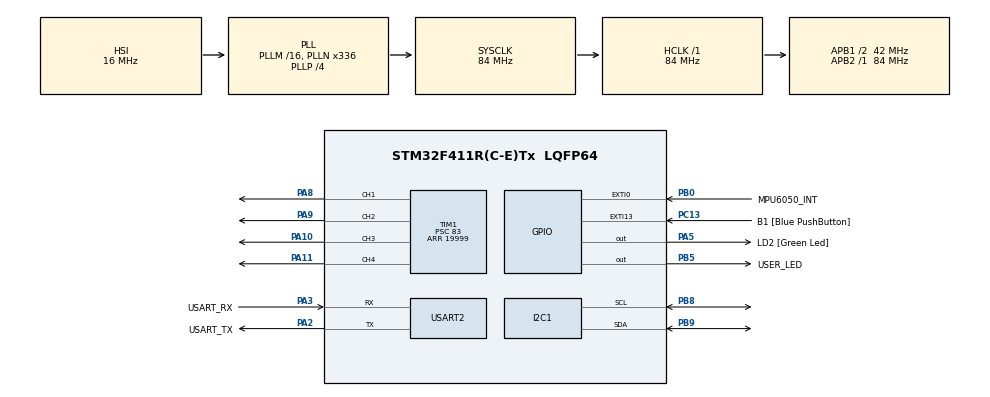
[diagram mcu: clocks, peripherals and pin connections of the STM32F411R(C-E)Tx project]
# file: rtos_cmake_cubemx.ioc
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Dma.I2C1_RX.0.Direction=DMA_PERIPH_TO_MEMORY
Dma.I2C1_RX.0.FIFOMode=DMA_FIFOMODE_DISABLE
Dma.I2C1_RX.0.Instance=DMA1_Stream0
Dma.I2C1_RX.0.MemDataAlignment=DMA_MDATAALIGN_BYTE
Dma.I2C1_RX.0.MemInc=DMA_MINC_ENABLE
Dma.I2C1_RX.0.Mode=DMA_NORMAL
Dma.I2C1_RX.0.PeriphDataAlignment=DMA_PDATAALIGN_BYTE
Dma.I2C1_RX.0.PeriphInc=DMA_PINC_DISABLE
Dma.I2C1_RX.0.Priority=DMA_PRIORITY_LOW
Dma.Request0=I2C1_RX
Dma.Request1=USART2_TX
Dma.USART2_TX.1.Direction=DMA_MEMORY_TO_PERIPH
Dma.USART2_TX.1.FIFOMode=DMA_FIFOMODE_DISABLE
Dma.USART2_TX.1.Instance=DMA1_Stream6
Dma.USART2_TX.1.MemDataAlignment=DMA_MDATAALIGN_BYTE
Dma.USART2_TX.1.MemInc=DMA_MINC_ENABLE
Dma.USART2_TX.1.Mode=DMA_NORMAL
Dma.USART2_TX.1.PeriphDataAlignment=DMA_PDATAALIGN_BYTE
Dma.USART2_TX.1.PeriphInc=DMA_PINC_DISABLE
Dma.USART2_TX.1.Priority=DMA_PRIORITY_MEDIUM
FREERTOS.Tasks01=defaultTask,24,128,StartDefaultTask,Default,NULL,Static,defaultTaskBuffer,defaultTaskControlBlock
I2C1.I2C_Mode=I2C_Fast
Mcu.Family=STM32F4
Mcu.Name=STM32F411R(C-E)Tx
Mcu.Package=LQFP64
NVIC.DMA1_Stream0_IRQn=true\:5\:0\:false\:false\:true\:true\:false\:true\:true
NVIC.DMA1_Stream6_IRQn=true\:5\:0\:false\:false\:true\:true\:false\:true\:true
NVIC.EXTI0_IRQn=true\:5\:0\:false\:false\:true\:false\:false\:true\:true
NVIC.I2C1_ER_IRQn=true\:5\:0\:false\:false\:true\:false\:false\:true\:true
NVIC.I2C1_EV_IRQn=true\:5\:0\:false\:false\:true\:false\:false\:true\:true
NVIC.PriorityGroup=NVIC_PRIORITYGROUP_4
NVIC.TIM1_UP_TIM10_IRQn=true\:5\:0\:true\:false\:true\:true\:false\:true\:true
NVIC.TimeBase=TIM1_UP_TIM10_IRQn
NVIC.TimeBaseIP=TIM10
NVIC.USART2_IRQn=true\:5\:0\:false\:false\:true\:true\:true\:true\:true
PA10.Signal=S_TIM1_CH3
PA11.Signal=S_TIM1_CH4
PA13.GPIO_Label=TMS
PA13.Mode=Serial_Wire
PA13.Signal=SYS_JTMS-SWDIO
PA14.GPIO_Label=TCK
PA14.Mode=Serial_Wire
PA14.Signal=SYS_JTCK-SWCLK
PA2.GPIO_Label=USART_TX
PA2.Mode=Asynchronous
PA2.Signal=USART2_TX
PA3.GPIO_Label=USART_RX
PA3.Mode=Asynchronous
PA3.Signal=USART2_RX
PA5.GPIO_Label=LD2 [Green Led]
PA5.Signal=GPIO_Output
PA8.Signal=S_TIM1_CH1
PA9.Signal=S_TIM1_CH2
PB0.GPIO_Label=MPU6050_INT
PB0.GPIO_ModeDefaultEXTI=GPIO_MODE_IT_FALLING
PB0.GPIO_PuPd=GPIO_PULLUP
PB0.Signal=GPXTI0
PB3.GPIO_Label=SWO
PB3.Signal=SYS_JTDO-SWO
PB5.GPIO_Label=USER_LED
PB5.Signal=GPIO_Output
PB8.Mode=I2C
PB8.Signal=I2C1_SCL
PB9.Mode=I2C
PB9.Signal=I2C1_SDA
PC13-ANTI_TAMP.GPIO_Label=B1 [Blue PushButton]
PC13-ANTI_TAMP.GPIO_ModeDefaultEXTI=GPIO_MODE_IT_FALLING
PC13-ANTI_TAMP.Signal=GPXTI13
PC14-OSC32_IN.Mode=LSE-External-Oscillator
PC14-OSC32_IN.Signal=RCC_OSC32_IN
PC15-OSC32_OUT.Mode=LSE-External-Oscillator
PC15-OSC32_OUT.Signal=RCC_OSC32_OUT
PH0\ -\ OSC_IN.Mode=HSE-External-Clock-Source
PH0\ -\ OSC_IN.Signal=RCC_OSC_IN
PH1\ -\ OSC_OUT.Mode=HSE-External-Clock-Source
PH1\ -\ OSC_OUT.Signal=RCC_OSC_OUT
ProjectManager.HeapSize=0x200
ProjectManager.StackSize=0x400
ProjectManager.TargetToolchain=CMake
RCC.48MHZClocksFreq_Value=84000000
RCC.AHBFreq_Value=84000000
RCC.APB1CLKDivider=RCC_HCLK_DIV2
RCC.APB1Freq_Value=42000000
RCC.APB1TimFreq_Value=84000000
RCC.APB2Freq_Value=84000000
RCC.APB2TimFreq_Value=84000000
RCC.CortexFreq_Value=84000000
RCC.FLatency-AdvancedSettings=FLASH_LATENCY_2
RCC.HCLKFreq_Value=84000000
RCC.HSE_VALUE=8000000
RCC.HSI_VALUE=16000000
RCC.PLLN=336
RCC.PLLP=RCC_PLLP_DIV4
RCC.SYSCLKFreq_VALUE=84000000
RCC.SYSCLKSource=RCC_SYSCLKSOURCE_PLLCLK
RCC.VCOOutputFreq_Value=336000000
SH.S_TIM1_CH1.0=TIM1_CH1,PWM Generation1 CH1
SH.S_TIM1_CH2.0=TIM1_CH2,PWM Generation2 CH2
SH.S_TIM1_CH3.0=TIM1_CH3,PWM Generation3 CH3
SH.S_TIM1_CH4.0=TIM1_CH4,PWM Generation4 CH4
TIM1.Channel-PWM\ Generation1\ CH1=TIM_CHANNEL_1
TIM1.Channel-PWM\ Generation2\ CH2=TIM_CHANNEL_2
TIM1.Channel-PWM\ Generation3\ CH3=TIM_CHANNEL_3
TIM1.Channel-PWM\ Generation4\ CH4=TIM_CHANNEL_4
TIM1.Period=19999
TIM1.Prescaler=83
TIM1.Pulse-PWM\ Generation1\ CH1=1500
TIM1.Pulse-PWM\ Generation2\ CH2=1500
TIM1.Pulse-PWM\ Generation3\ CH3=1500
TIM1.Pulse-PWM\ Generation4\ CH4=1500
USART2.VirtualMode=VM_ASYNC
VP_FREERTOS_VS_CMSIS_V2.Mode=CMSIS_V2
VP_SYS_VS_tim10.Mode=TIM10
VP_TIM1_VS_ClockSourceINT.Mode=Internal
board=NUCLEO-F411RE

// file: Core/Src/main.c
/* USER CODE BEGIN Header */
/**
  ******************************************************************************
  * @file           : main.c
  * @brief          : Main program body
  ******************************************************************************
  * @attention
  *
  * Copyright (c) 2026 STMicroelectronics.
  * All rights reserved.
  *
  * This software is licensed under terms that can be found in the LICENSE file
  * in the root directory of this software component.
  * If no LICENSE file comes with this software, it is provided AS-IS.
  *
  ******************************************************************************
  */
/* USER CODE END Header */
#include "main.h"
#include "cmsis_os.h"

/* USER CODE BEGIN Includes */
#include "app_platform_port.h"

/* USER CODE END Includes */

typedef StaticTask_t osStaticThreadDef_t;

I2C_HandleTypeDef hi2c1;
DMA_HandleTypeDef hdma_i2c1_rx;

TIM_HandleTypeDef htim1;

UART_HandleTypeDef huart2;
DMA_HandleTypeDef hdma_usart2_tx;

/* Definitions for defaultTask */
osThreadId_t defaultTaskHandle;
uint32_t defaultTaskBuffer[ 512 ];
osStaticThreadDef_t defaultTaskControlBlock;
const osThreadAttr_t defaultTask_attributes = {
  .name = "defaultTask",
  .cb_mem = &defaultTaskControlBlock,
  .cb_size = sizeof(defaultTaskControlBlock),
  .stack_mem = &defaultTaskBuffer[0],
  .stack_size = sizeof(defaultTaskBuffer),
  .priority = (osPriority_t) osPriorityNormal,
};

void SystemClock_Config(void);
static void MX_GPIO_Init(void);
static void MX_DMA_Init(void);
static void MX_I2C1_Init(void);
static void MX_USART2_UART_Init(void);
static void MX_TIM1_Init(void);
void StartDefaultTask(void *argument);

int main(void)
{

  /* MCU Configuration--------------------------------------------------------*/

  /* Reset of all peripherals, Initializes the Flash interface and the Systick. */
  HAL_Init();

  /* Configure the system clock */
  SystemClock_Config();

  /* Initialize all configured peripherals */
  MX_GPIO_Init();
  MX_DMA_Init();
  MX_I2C1_Init();
  MX_USART2_UART_Init();
  MX_TIM1_Init();

  /* Init scheduler */
  osKernelInitialize();

  /* USER CODE BEGIN RTOS_MUTEX */
  /* AppPlatformPort_Init runs from StartDefaultTask after osKernelStart so
     driver startup delays use osDelay instead of blocking on HAL tick. */
  /* USER CODE END RTOS_MUTEX */

  /* Create the thread(s) */
  /* creation of defaultTask */
  defaultTaskHandle = osThreadNew(StartDefaultTask, NULL, &defaultTask_attributes);

  /* USER CODE BEGIN RTOS_THREADS */
  /* Sensor/telemetry tasks are created from StartDefaultTask after platform init. */
  /* USER CODE END RTOS_THREADS */

  /* Start scheduler */
  osKernelStart();

  /* We should never get here as control is now taken by the scheduler */

  /* Infinite loop */
  while (1)
  {

  }
}

void SystemClock_Config(void)
{
  RCC_OscInitTypeDef RCC_OscInitStruct = {0};
  RCC_ClkInitTypeDef RCC_ClkInitStruct = {0};

  /** Configure the main internal regulator output voltage
  */
  __HAL_RCC_PWR_CLK_ENABLE();
  __HAL_PWR_VOLTAGESCALING_CONFIG(PWR_REGULATOR_VOLTAGE_SCALE1);

  /** Initializes the RCC Oscillators according to the specified parameters
  * in the RCC_OscInitTypeDef structure.
  */
  RCC_OscInitStruct.OscillatorType = RCC_OSCILLATORTYPE_HSI;
  RCC_OscInitStruct.HSIState = RCC_HSI_ON;
  RCC_OscInitStruct.HSICalibrationValue = RCC_HSICALIBRATION_DEFAULT;
  RCC_OscInitStruct.PLL.PLLState = RCC_PLL_ON;
  RCC_OscInitStruct.PLL.PLLSource = RCC_PLLSOURCE_HSI;
  RCC_OscInitStruct.PLL.PLLM = 16;
  RCC_OscInitStruct.PLL.PLLN = 336;
  RCC_OscInitStruct.PLL.PLLP = RCC_PLLP_DIV4;
  RCC_OscInitStruct.PLL.PLLQ = 4;
  if (HAL_RCC_OscConfig(&RCC_OscInitStruct) != HAL_OK)
  {
    Error_Handler();
  }

  /** Initializes the CPU, AHB and APB buses clocks
  */
  RCC_ClkInitStruct.ClockType = RCC_CLOCKTYPE_HCLK|RCC_CLOCKTYPE_SYSCLK
                              |RCC_CLOCKTYPE_PCLK1|RCC_CLOCKTYPE_PCLK2;
  RCC_ClkInitStruct.SYSCLKSource = RCC_SYSCLKSOURCE_PLLCLK;
  RCC_ClkInitStruct.AHBCLKDivider = RCC_SYSCLK_DIV1;
  RCC_ClkInitStruct.APB1CLKDivider = RCC_HCLK_DIV2;
  RCC_ClkInitStruct.APB2CLKDivider = RCC_HCLK_DIV1;

  if (HAL_RCC_ClockConfig(&RCC_ClkInitStruct, FLASH_LATENCY_2) != HAL_OK)
  {
    Error_Handler();
  }
}

static void MX_I2C1_Init(void)
{

  hi2c1.Instance = I2C1;
  hi2c1.Init.ClockSpeed = 400000;
  hi2c1.Init.DutyCycle = I2C_DUTYCYCLE_2;
  hi2c1.Init.OwnAddress1 = 0;
  hi2c1.Init.AddressingMode = I2C_ADDRESSINGMODE_7BIT;
  hi2c1.Init.DualAddressMode = I2C_DUALADDRESS_DISABLE;
  hi2c1.Init.OwnAddress2 = 0;
  hi2c1.Init.GeneralCallMode = I2C_GENERALCALL_DISABLE;
  hi2c1.Init.NoStretchMode = I2C_NOSTRETCH_DISABLE;
  if (HAL_I2C_Init(&hi2c1) != HAL_OK)
  {
    Error_Handler();
  }

}

static void MX_TIM1_Init(void)
{

  TIM_ClockConfigTypeDef sClockSourceConfig = {0};
  TIM_MasterConfigTypeDef sMasterConfig = {0};
  TIM_OC_InitTypeDef sConfigOC = {0};
  TIM_BreakDeadTimeConfigTypeDef sBreakDeadTimeConfig = {0};

  htim1.Instance = TIM1;
  htim1.Init.Prescaler = 83;
  htim1.Init.CounterMode = TIM_COUNTERMODE_UP;
  htim1.Init.Period = 19999;
  htim1.Init.ClockDivision = TIM_CLOCKDIVISION_DIV1;
  htim1.Init.RepetitionCounter = 0;
  htim1.Init.AutoReloadPreload = TIM_AUTORELOAD_PRELOAD_DISABLE;
  if (HAL_TIM_Base_Init(&htim1) != HAL_OK)
  {
    Error_Handler();
  }
  sClockSourceConfig.ClockSource = TIM_CLOCKSOURCE_INTERNAL;
  if (HAL_TIM_ConfigClockSource(&htim1, &sClockSourceConfig) != HAL_OK)
  {
    Error_Handler();
  }
  if (HAL_TIM_PWM_Init(&htim1) != HAL_OK)
  {
    Error_Handler();
  }
  sMasterConfig.MasterOutputTrigger = TIM_TRGO_RESET;
  sMasterConfig.MasterSlaveMode = TIM_MASTERSLAVEMODE_DISABLE;
  if (HAL_TIMEx_MasterConfigSynchronization(&htim1, &sMasterConfig) != HAL_OK)
  {
    Error_Handler();
  }
  sConfigOC.OCMode = TIM_OCMODE_PWM1;
  sConfigOC.Pulse = 1500;
  sConfigOC.OCPolarity = TIM_OCPOLARITY_HIGH;
  sConfigOC.OCNPolarity = TIM_OCNPOLARITY_HIGH;
  sConfigOC.OCFastMode = TIM_OCFAST_DISABLE;
  sConfigOC.OCIdleState = TIM_OCIDLESTATE_RESET;
  sConfigOC.OCNIdleState = TIM_OCNIDLESTATE_RESET;
  if (HAL_TIM_PWM_ConfigChannel(&htim1, &sConfigOC, TIM_CHANNEL_1) != HAL_OK)
  {
    Error_Handler();
  }
  if (HAL_TIM_PWM_ConfigChannel(&htim1, &sConfigOC, TIM_CHANNEL_2) != HAL_OK)
  {
    Error_Handler();
  }
  if (HAL_TIM_PWM_ConfigChannel(&htim1, &sConfigOC, TIM_CHANNEL_3) != HAL_OK)
  {
    Error_Handler();
  }
  if (HAL_TIM_PWM_ConfigChannel(&htim1, &sConfigOC, TIM_CHANNEL_4) != HAL_OK)
  {
    Error_Handler();
  }
  sBreakDeadTimeConfig.OffStateRunMode = TIM_OSSR_DISABLE;
  sBreakDeadTimeConfig.OffStateIDLEMode = TIM_OSSI_DISABLE;
  sBreakDeadTimeConfig.LockLevel = TIM_LOCKLEVEL_OFF;
  sBreakDeadTimeConfig.DeadTime = 0;
  sBreakDeadTimeConfig.BreakState = TIM_BREAK_DISABLE;
  sBreakDeadTimeConfig.BreakPolarity = TIM_BREAKPOLARITY_HIGH;
  sBreakDeadTimeConfig.AutomaticOutput = TIM_AUTOMATICOUTPUT_DISABLE;
  if (HAL_TIMEx_ConfigBreakDeadTime(&htim1, &sBreakDeadTimeConfig) != HAL_OK)
  {
    Error_Handler();
  }
  HAL_TIM_MspPostInit(&htim1);

}

static void MX_USART2_UART_Init(void)
{

  huart2.Instance = USART2;
  huart2.Init.BaudRate = 115200;
  huart2.Init.WordLength = UART_WORDLENGTH_8B;
  huart2.Init.StopBits = UART_STOPBITS_1;
  huart2.Init.Parity = UART_PARITY_NONE;
  huart2.Init.Mode = UART_MODE_TX_RX;
  huart2.Init.HwFlowCtl = UART_HWCONTROL_NONE;
  huart2.Init.OverSampling = UART_OVERSAMPLING_16;
  if (HAL_UART_Init(&huart2) != HAL_OK)
  {
    Error_Handler();
  }

}

static void MX_DMA_Init(void)
{

  /* DMA controller clock enable */
  __HAL_RCC_DMA1_CLK_ENABLE();

  /* DMA interrupt init */
  /* DMA1_Stream0_IRQn interrupt configuration */
  HAL_NVIC_SetPriority(DMA1_Stream0_IRQn, 5, 0);
  HAL_NVIC_EnableIRQ(DMA1_Stream0_IRQn);
  /* DMA1_Stream6_IRQn interrupt configuration */
  HAL_NVIC_SetPriority(DMA1_Stream6_IRQn, 5, 0);
  HAL_NVIC_EnableIRQ(DMA1_Stream6_IRQn);

}

static void MX_GPIO_Init(void)
{
  GPIO_InitTypeDef GPIO_InitStruct = {0};

  /* GPIO Ports Clock Enable */
  __HAL_RCC_GPIOC_CLK_ENABLE();
  __HAL_RCC_GPIOH_CLK_ENABLE();
  __HAL_RCC_GPIOA_CLK_ENABLE();
  __HAL_RCC_GPIOB_CLK_ENABLE();

  /*Configure GPIO pin Output Level */
  HAL_GPIO_WritePin(LD2_GPIO_Port, LD2_Pin, GPIO_PIN_RESET);

  /*Configure GPIO pin Output Level */
  HAL_GPIO_WritePin(USER_LED_GPIO_Port, USER_LED_Pin, GPIO_PIN_RESET);

  /*Configure GPIO pin : B1_Pin */
  GPIO_InitStruct.Pin = B1_Pin;
  GPIO_InitStruct.Mode = GPIO_MODE_IT_FALLING;
  GPIO_InitStruct.Pull = GPIO_NOPULL;
  HAL_GPIO_Init(B1_GPIO_Port, &GPIO_InitStruct);

  /*Configure GPIO pin : LD2_Pin */
  GPIO_InitStruct.Pin = LD2_Pin;
  GPIO_InitStruct.Mode = GPIO_MODE_OUTPUT_PP;
  GPIO_InitStruct.Pull = GPIO_NOPULL;
  GPIO_InitStruct.Speed = GPIO_SPEED_FREQ_LOW;
  HAL_GPIO_Init(LD2_GPIO_Port, &GPIO_InitStruct);

  /*Configure GPIO pin : MPU6050_INT_Pin */
  GPIO_InitStruct.Pin = MPU6050_INT_Pin;
  GPIO_InitStruct.Mode = GPIO_MODE_IT_FALLING;
  GPIO_InitStruct.Pull = GPIO_PULLUP;
  HAL_GPIO_Init(MPU6050_INT_GPIO_Port, &GPIO_InitStruct);

  /*Configure GPIO pin : USER_LED_Pin */
  GPIO_InitStruct.Pin = USER_LED_Pin;
  GPIO_InitStruct.Mode = GPIO_MODE_OUTPUT_PP;
  GPIO_InitStruct.Pull = GPIO_NOPULL;
  GPIO_InitStruct.Speed = GPIO_SPEED_FREQ_LOW;
  HAL_GPIO_Init(USER_LED_GPIO_Port, &GPIO_InitStruct);

  /* EXTI interrupt init*/
  HAL_NVIC_SetPriority(EXTI0_IRQn, 5, 0);
  HAL_NVIC_EnableIRQ(EXTI0_IRQn);

}

/* USER CODE BEGIN 4 */
void HAL_GPIO_EXTI_Callback(uint16_t GPIO_Pin)
{
  AppPlatformPort_OnExtiCallback(GPIO_Pin);
}

void HAL_I2C_MemRxCpltCallback(I2C_HandleTypeDef *hi2c)
{
  AppPlatformPort_OnI2cMemRxComplete(hi2c);
}

void HAL_UART_TxCpltCallback(UART_HandleTypeDef *huart)
{
  AppPlatformPort_OnUartTxComplete(huart);
}

void HAL_UART_ErrorCallback(UART_HandleTypeDef *huart)
{
  AppPlatformPort_OnUartError(huart);
}

/* USER CODE END 4 */

void StartDefaultTask(void *argument)
{
  /* USER CODE BEGIN 5 */
  if (AppPlatformPort_Init(&hi2c1, &huart2, &htim1) == false)
  {
    Error_Handler();
  }

  if (AppPlatformPort_CreateTask() == NULL)
  {
    Error_Handler();
  }

  for (;;)
  {
    //osDelay(1000);
    osThreadSuspend(osThreadGetId());
  }
  /* USER CODE END 5 */
}

void HAL_TIM_PeriodElapsedCallback(TIM_HandleTypeDef *htim)
{
  if (htim->Instance == TIM10)
  {
    HAL_IncTick();
  }
}

void Error_Handler(void)
{
  __disable_irq();
  while (1)
  {
  }
}
